# K1921VG5T register map
Vendor: NIIET; Series: K1921VKx; File version: 1.1
CPU: CM4 r0p1, Endian.LITTLE endian, MPU, FPU
Registers are 32-bit, read-write, reset 0x0 unless marked. A register's access mark holds for its fields unless they carry their own. Offsets are from the block's base; [hi:lo] are bit positions; lines under a group give offsets from that group; {n}, {i} and the like mark numbered series; 'fields as' and 'values as' point back to an identical list.

## RCU — Reset and clock unit
Base 0x50004000
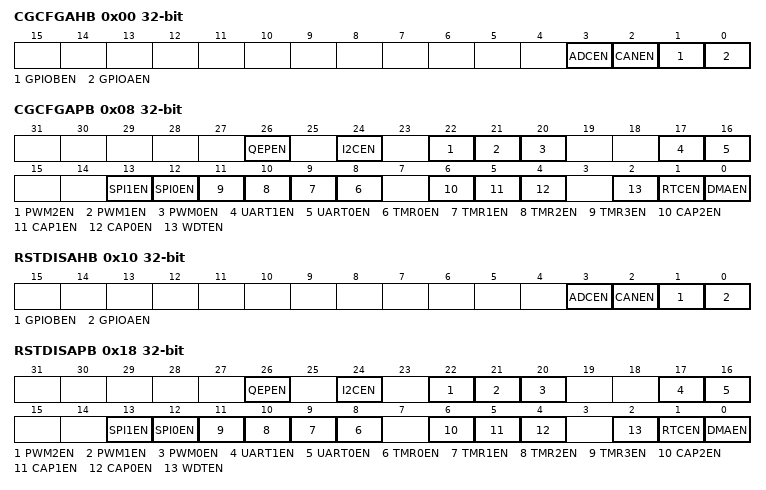
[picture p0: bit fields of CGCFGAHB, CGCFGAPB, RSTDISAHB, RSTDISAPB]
0x00 CGCFGAHB — Clockgate AHB configuration register
  [3] ADCEN — Enable clock ADC
  [2] CANEN — Enable clock CAN
  [1] GPIOBEN — Enable clock GPIOB
  [0] GPIOAEN — Enable clock GPIOA
0x08 CGCFGAPB — Clockgate APB configuration register
  [26] QEPEN — Enable clock QEP
  [24] I2CEN — Enable clock I2C
  [22] PWM2EN — Enable clock PWM2
  [21] PWM1EN — Enable clock PWM1
  [20] PWM0EN — Enable clock PWM0
  [17] UART1EN — Enable clock UART1
  [16] UART0EN — Enable clock UART0
  [13] SPI1EN — Enable clock SPI1
  [12] SPI0EN — Enable clock SPI0
  [n+8] TMR{n}EN (n=0..3) — Enable clock TMR{n}
  [6] CAP2EN — Enable clock I2C
  [5] CAP1EN — Enable clock TRNG
  [4] CAP0EN — Enable clock TMR2
  [2] WDTEN — Enable clock TMR1
  [1] RTCEN — Enable clock I2C
  [0] DMAEN — Enable clock WDT
0x10 RSTDISAHB — Reset disable AHB configuration register
  [3] ADCEN — Disable reset ADC
  [2] CANEN — Disable reset CAN
  [1] GPIOBEN — Disable reset GPIOB
  [0] GPIOAEN — Disable reset GPIOA
0x18 RSTDISAPB — Reset disable APB register
  [26] QEPEN — Disable reset QEP
  [24] I2CEN — Disable reset I2C
  [22] PWM2EN — Disable reset PWM2
  [21] PWM1EN — Disable reset PWM1
  [20] PWM0EN — Disable reset PWM0
  [17] UART1EN — Disable reset UART1
  [16] UART0EN — Disable reset UART0
  [13] SPI1EN — Disable reset SPI1
  [12] SPI0EN — Disable reset SPI0
  [n+8] TMR{n}EN (n=0..3) — Disable reset TMR{n}
  [6] CAP2EN — Disable reset I2C
  [5] CAP1EN — Disable reset TRNG
  [4] CAP0EN — Disable reset TMR2
  [2] WDTEN — Disable reset TMR1
  [1] RTCEN — Disable reset I2C
  [0] DMAEN — Disable reset WDT
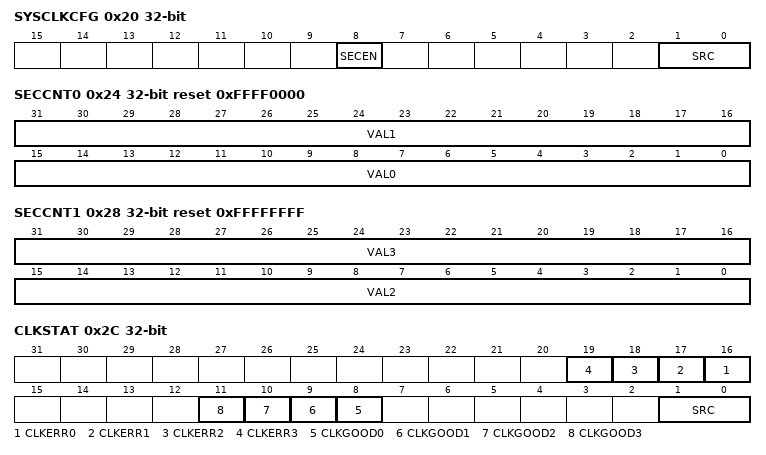
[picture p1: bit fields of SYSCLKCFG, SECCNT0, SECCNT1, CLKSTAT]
0x20 SYSCLKCFG — System clock configuration register
  [8] SECEN
  [1:0] SRC — System clock source
    0=HSICLK (HSI 4MHz); 1=HSECLK (HSE(XTAL)); 2=PLLCLK (Clock from PLL); 3=EXTCLK (external CLK from gpio pin)
0x24 SECCNT0 reset 0xFFFF0000 — Security counter configuration 0 register
  [31:16] VAL1, [15:0] VAL0
0x28 SECCNT1 reset 0xFFFFFFFF — Security counter configuration 1 register
  [31:16] VAL3, [15:0] VAL2
0x2C CLKSTAT ro — System clock status register
  [n+16] CLKERR{n} (n=0..3)
  [n+8] CLKGOOD{n} (n=0..3)
  [1:0] SRC — HSICLK:0:HSI 4MHz;HSECLK:1:HSE(XTAL);PLLCLK:2: Clock from PLL;EXTCLK:3: external CLK from gpio pin;
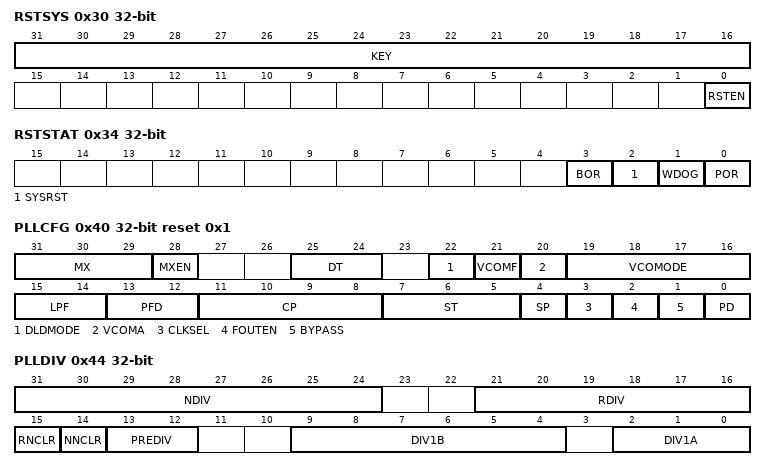
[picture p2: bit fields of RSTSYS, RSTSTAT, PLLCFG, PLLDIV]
0x30 RSTSYS wo — System Reset Register
  [31:16] KEY — KEY 'A55A' in hexadecimal for unblocking
  [0] RSTEN — Reset enable
0x34 RSTSTAT — Reset Status Register
  [3] BOR — BOR Reset status
  [2] SYSRST — System Reset Status
  [1] WDOG — WatchDog Reset status
  [0] POR — PowerOn Reset status
0x40 PLLCFG reset 0x1 — PLL Configuration Register
  [31:29] MX — Test mux signal select
  [28] MXEN — Test mux enable
  [25:24] DT — fractional noise randomization mode
  [22] DLDMODE — Frequency detector delay
  [21] VCOMF — Ajust lower range of GUN
  [20] VCOMA — Ajust amplitude of GUN
  [19:16] VCOMODE — Subband selection signal
  [15:14] LPF — Loop filter band
  [13:12] PFD — Mode of current switch
  [11:8] CP — Output current of current switch
  [7:5] ST — Sggma-delta modulator mode
  [4] SP — Song-Park mode
  [3] CLKSEL — HSECLK:0:HSE(XTAL);EXTCLK:1: external CLK from gpio pin;
  [2] FOUTEN — Fout enable
  [1] BYPASS — Bypass enable
  [0] PD — Powerdown enable
0x44 PLLDIV — PLL DIV Configuration Register
  [31:24] NDIV — Integer part of divider
  [21:16] RDIV — R-divider coefficient
  [15] RNCLR — R-divider enable
  [14] NNCLR — N-divider enable
  [13:12] PREDIV — Predivisor coefficient
  [9:4] DIV1B — Divider 1B
  [2:0] DIV1A — Divider 1A
0x48 PLLFRAC — PLL FRAC Configuration Register
  [23:0] FRAC — numerator of fractional part
0x4C PLLMOD — PLL MOD Configuration Register
  [23:0] MOD — denominator of fractional part
{0x60+4i} UARTCFG[{i}] (i=0..1) group
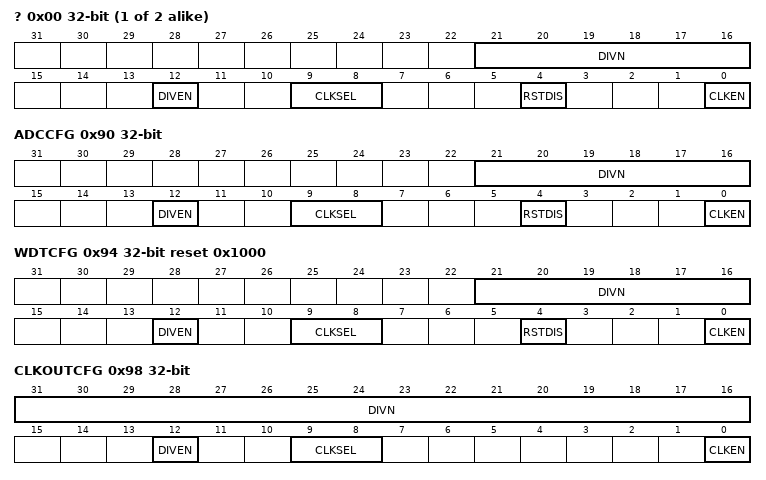
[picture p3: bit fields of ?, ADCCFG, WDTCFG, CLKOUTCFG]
  0x00 ? — UART Clock and Reset Configuration Register
    [21:16] DIVN — Divider coefficient
    [12] DIVEN — Enable divider
    [9:8] CLKSEL — Clock source select
      values as SYSCLKCFG.SRC
    [4] RSTDIS — Reset disable
    [0] CLKEN — Clock enable
{0x80+4i} SPICFG[{i}] (i=0..1) group
  0x00 ? — SPI Clock and Reset Configuration Register
    fields as UARTCFG[0].?
0x90 ADCCFG — ADC Clock and Reset Configuration Register
  fields as UARTCFG[0].?
0x94 WDTCFG reset 0x1000 — WatchDog Configuration Register
  fields as UARTCFG[0].?
0x98 CLKOUTCFG — Clockout Configuration Register
  [31:16] DIVN — Divider coefficient
  [12] DIVEN — Enable divider
  [9:8] CLKSEL — Clock source select
    0=HSICLK (HSI 4MHz); 1=HSECLK (HSE(XTAL)); 2=PLLCLK (Clock from PLL); 3=RTCCLK (CLK from RTC (LSI or LSE))
  [0] CLKEN — Clock enable
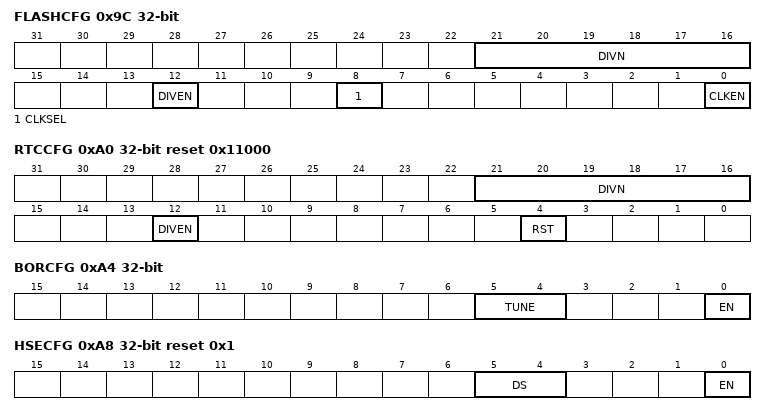
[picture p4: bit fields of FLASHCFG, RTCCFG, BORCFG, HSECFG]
0x9C FLASHCFG — Flash Configuration Register
  [21:16] DIVN — Divider coefficient
  [12] DIVEN — Enable divider
  [8] CLKSEL — Clock source select
    0=HSICLK (HSI 4MHz); 1=HSECLK (HSE(XTAL))
  [0] CLKEN — Clock enable
0xA0 RTCCFG reset 0x11000 — RTC APB clock divider
  [21:16] DIVN — Divider coefficient
  [12] DIVEN — Enable divider
  [4] RST — Reset active High
0xA4 BORCFG — BOR Configuration Register
  [5:4] TUNE — Tune BOR level
  [0] EN — Enable BOR
0xA8 HSECFG reset 0x1 — HSE Configuration Register
  [5:4] DS — Drive current select pins
  [0] EN — Enable HSE pins
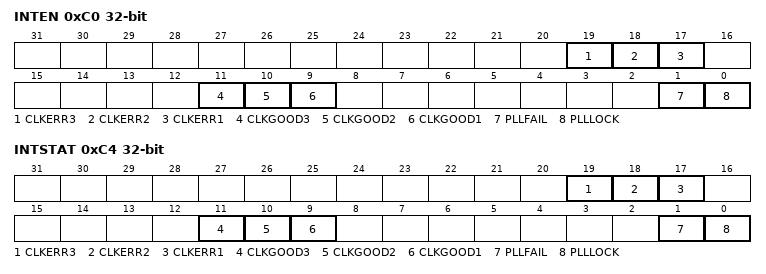
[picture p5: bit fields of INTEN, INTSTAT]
0xC0 INTEN — Interrupt enable reigster
  [19] CLKERR3
  [18] CLKERR2
  [17] CLKERR1
  [11] CLKGOOD3
  [10] CLKGOOD2
  [9] CLKGOOD1
  [1] PLLFAIL — Enable PLL fail to lock interrupt
  [0] PLLLOCK — Enable PLL lock interrupt
0xC4 INTSTAT wo — Interrupt status register
  [19] CLKERR3, [18] CLKERR2, [17] CLKERR1, [11] CLKGOOD3, [10] CLKGOOD2, [9] CLKGOOD1, [1] PLLFAIL, [0] PLLLOCK
